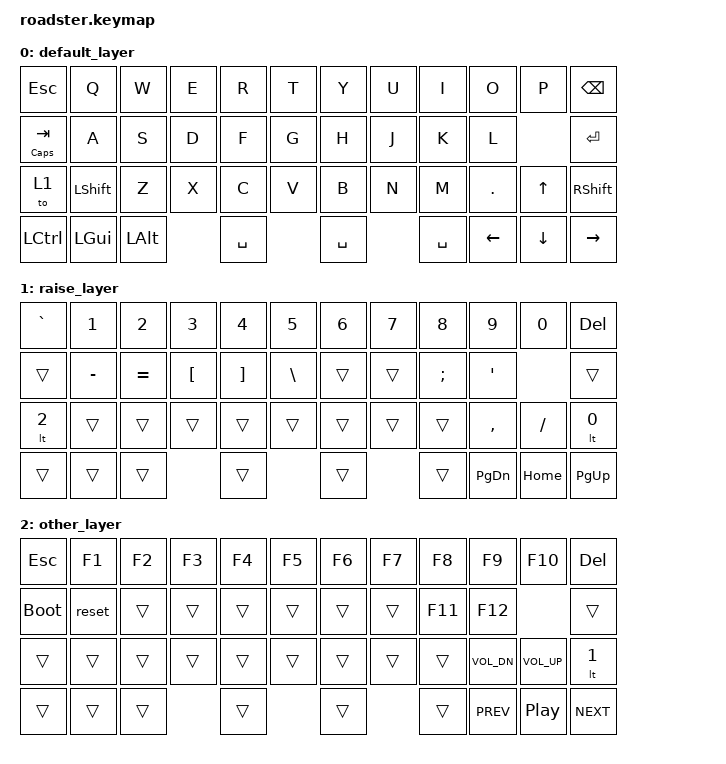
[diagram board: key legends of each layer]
/*
 * Copyright (c) 2020 The ZMK Contributors
 *
 * SPDX-License-Identifier: MIT
 */

#include <behaviors.dtsi>
#include <dt-bindings/zmk/keys.h>
#include <dt-bindings/zmk/bt.h>

/ {
        behaviors {
		ht: hold_tap {
			compatible = "zmk,behavior-hold-tap";
			label = "Hold Tap";
			#binding-cells = <2>;
			tapping-term-ms = <200>;
			flavor = "tap-preferred";
			bindings = <&kp>, <&kp>;
		};
	};
        
        keymap {
                compatible = "zmk,keymap";

                default_layer {
// -------------------------------------------------------------------------------------
// | ESC |  Q  |  W  |  E  |  R  |  T  |   |  Y  |  U  |  I  |  O  |  P  | BKSP|
// | TAB |  A  |  S  |  D  |  F  |  G  |   |  H  |  J  |  K  |  L  |    RET    |
// | RSE | LSH |  Z  |  X  |  C  |  V  |   |  B  |  N  |  M  |  .  |  UP | RSH |
// | CTRL| SYS | ALT |    SPC    |      SPC      |    SPC    | LFT | DWN | RGT |
                        bindings = <
   &kp ESC      &kp Q &kp W &kp E &kp R &kp T   &kp Y &kp U  &kp I     &kp O   &kp P    &kp BSPC
   &ht CAPS TAB &kp A &kp S &kp D &kp F &kp G   &kp H &kp J  &kp K     &kp L            &kp RET
   &to 1    &kp LSHFT &kp Z &kp X &kp C &kp V   &kp B &kp N  &kp M     &kp DOT &kp UP   &kp RSHFT
   &kp LCTRL &kp LGUI &kp LALT    &kp SPACE    &kp SPACE    &kp SPACE  &kp LEFT &kp DOWN &kp RIGHT
                        >;
                };

                raise_layer {
// -------------------------------------------------------------------------------------
// |  `  |  1  |  2  |  3  |  4  |  5  |   |  6  |  7  |  8  |  9  |  0  | DEL |
// |     |  -  |  =  |  [  |  ]  |  \  |   |     |     |  ;  |  '  |           |
// | RSE |     |     |     |     |     |   |     |     |     |  ,  |  /  | LWR |
// |     |     |     |           |               |           |PG_UP| HOME|PG_DN|
                        bindings = <
   &kp GRAVE &kp N1 &kp N2 &kp N3 &kp N4 &kp N5 &kp N6 &kp N7 &kp N8 &kp N9 &kp N0  &kp DEL
   &trans &kp MINUS &kp EQUAL &kp LBKT &kp RBKT &kp BSLH &trans &trans &kp SEMI &kp SQT &trans
   &lt 2 &trans &trans &trans &trans &trans &trans &trans &trans &kp COMMA &kp FSLH &lt 0
   &trans &trans &trans &trans &trans &trans &kp PG_DN &kp HOME &kp PG_UP
                        >;
                };

                other_layer {
// -----------------------------------------------------------------------------------------
// |     |  F1 |  F2 |  F3 |  F4 |  F5 |   |  F6 |  F7 |  F8 |  F9 | F10 | DEL |
// | BLDR| RST |     |     |     |     |   |     |     | F11 | F12 |           |
// |     |     |     |     |     |     |   |     |     |     | VDN | VUP | LWR |
// |     |     |     |           |               |           | PRV |  PP | NXT |
                        bindings = <
   &kp ESC &kp F1 &kp F2 &kp F3 &kp F4 &kp F5 &kp F6 &kp F7 &kp F8 &kp F9 &kp F10 &kp DEL
   &bootloader &reset &trans &trans &trans &trans &trans &trans &kp F11 &kp F12 &trans
   &trans &trans &trans &trans &trans &trans &trans &trans &trans &kp C_VOL_DN &kp C_VOL_UP &lt 1
   &trans &trans &trans &trans &trans &trans &kp C_PREV &kp C_PP &kp C_NEXT
                        >;
                };
	};
};
